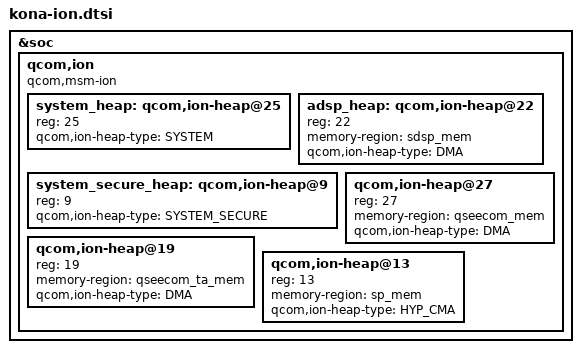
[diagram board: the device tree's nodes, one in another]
// SPDX-License-Identifier: GPL-2.0-only
/*
 * Copyright (c) 2018-2019, The Linux Foundation. All rights reserved.
 */

&soc {
	qcom,ion {
		compatible = "qcom,msm-ion";
		#address-cells = <1>;
		#size-cells = <0>;

		system_heap: qcom,ion-heap@25 {
			reg = <25>;
			qcom,ion-heap-type = "SYSTEM";
		};

		adsp_heap: qcom,ion-heap@22 {
			reg = <22>;
			memory-region = <&sdsp_mem>;
			qcom,ion-heap-type = "DMA";
		};

		system_secure_heap: qcom,ion-heap@9 {
			reg = <9>;
			qcom,ion-heap-type = "SYSTEM_SECURE";
		};

		qcom,ion-heap@27 { /* QSEECOM HEAP */
			reg = <27>;
			memory-region = <&qseecom_mem>;
			qcom,ion-heap-type = "DMA";
		};

		qcom,ion-heap@19 { /* QSEECOM TA HEAP */
			reg = <19>;
			memory-region = <&qseecom_ta_mem>;
			qcom,ion-heap-type = "DMA";
		};

		qcom,ion-heap@13 { /* SPSS HEAP */
			reg = <13>;
			memory-region = <&sp_mem>;
			qcom,ion-heap-type = "HYP_CMA";
		};
	};
};
